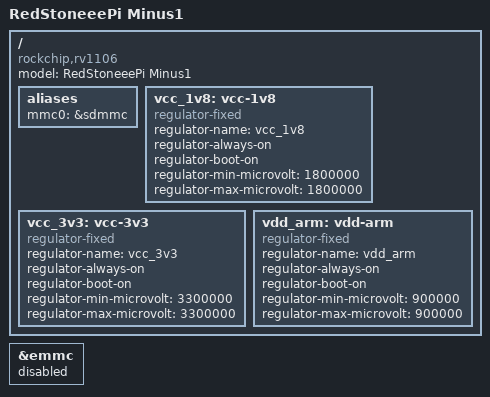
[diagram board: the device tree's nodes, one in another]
// SPDX-License-Identifier: (GPL-2.0+ OR MIT)
/*
* Copyright (c) 2022 Rockchip Electronics Co., Ltd.
*/
/dts-v1/;

#include "rv1106.dtsi"
#include "rv1106-u-boot.dtsi"
#include <dt-bindings/input/input.h>

/ {
	model = "RedStoneeePi Minus1";
	compatible = "rockchip,rv1106";
	
	aliases {
		mmc0 = &sdmmc;
	};


	vcc_1v8: vcc-1v8 {
		compatible = "regulator-fixed";
		regulator-name = "vcc_1v8";
		regulator-always-on;
		regulator-boot-on;
		regulator-min-microvolt = <1800000>;
		regulator-max-microvolt = <1800000>;
	};
	
	vcc_3v3: vcc-3v3 {
		compatible = "regulator-fixed";
		regulator-name = "vcc_3v3";
		regulator-always-on;
		regulator-boot-on;
		regulator-min-microvolt = <3300000>;
		regulator-max-microvolt = <3300000>;
	};
	
	vdd_arm: vdd-arm {
		compatible = "regulator-fixed";
		regulator-name = "vdd_arm";
		regulator-always-on;
		regulator-boot-on;
		regulator-min-microvolt = <900000>;
		regulator-max-microvolt = <900000>;
	};
};

&emmc {
	status = "disabled";
};
	


